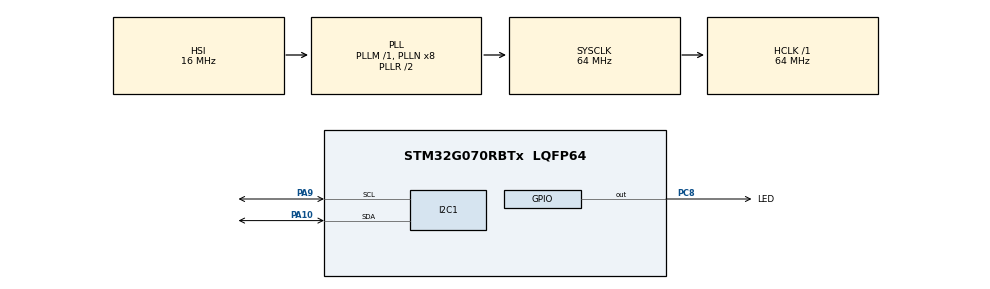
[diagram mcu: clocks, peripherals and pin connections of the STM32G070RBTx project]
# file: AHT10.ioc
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I2C1.Timing=0x10707DBC
Mcu.Family=STM32G0
Mcu.Name=STM32G070RBTx
Mcu.Package=LQFP64
NVIC.I2C1_IRQn=true\:0\:0\:false\:false\:true\:true\:true
PA10.Mode=I2C
PA10.Signal=I2C1_SDA
PA9.Mode=I2C
PA9.Signal=I2C1_SCL
PC8.GPIO_Label=LED
PC8.PinState=GPIO_PIN_SET
PC8.Signal=GPIO_Output
PF0-OSC_IN\ (PF0).Mode=HSE-External-Oscillator
PF0-OSC_IN\ (PF0).Signal=RCC_OSC_IN
PF1-OSC_OUT\ (PF1).Mode=HSE-External-Oscillator
PF1-OSC_OUT\ (PF1).Signal=RCC_OSC_OUT
ProjectManager.HeapSize=0x200
ProjectManager.StackSize=0x400
ProjectManager.TargetToolchain=MDK-ARM V5.32
RCC.ADCFreq_Value=64000000
RCC.AHBFreq_Value=64000000
RCC.CortexFreq_Value=64000000
RCC.EXTERNAL_CLOCK_VALUE=48000
RCC.HCLKFreq_Value=64000000
RCC.HSE_VALUE=12000000
RCC.HSI_VALUE=16000000
RCC.LSE_VALUE=32768
RCC.SYSCLKFreq_VALUE=64000000
RCC.SYSCLKSource=RCC_SYSCLKSOURCE_PLLCLK
RCC.VCOOutputFreq_Value=128000000
VP_SYS_VS_DBSignals.Mode=DisableDeadBatterySignals
board=custom

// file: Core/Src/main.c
/* USER CODE BEGIN Header */
/**
  ******************************************************************************
  * @file           : main.c
  * @brief          : Main program body
  ******************************************************************************
  * @attention
  *
  * Copyright (c) 2022 STMicroelectronics.
  * All rights reserved.
  *
  * This software is licensed under terms that can be found in the LICENSE file
  * in the root directory of this software component.
  * If no LICENSE file comes with this software, it is provided AS-IS.
  *
  ******************************************************************************
  */
/* USER CODE END Header */
#include "main.h"
#include "i2c.h"
#include "gpio.h"

/* USER CODE BEGIN Includes */
#include "aht10.h"
/* USER CODE END Includes */

void SystemClock_Config(void);

int main(void)
{
  /* USER CODE BEGIN 1 */
	AHT10_DATA aht10_data;
  /* USER CODE END 1 */

  /* MCU Configuration--------------------------------------------------------*/

  /* Reset of all peripherals, Initializes the Flash interface and the Systick. */
  HAL_Init();

  /* Configure the system clock */
  SystemClock_Config();

  /* Initialize all configured peripherals */
  MX_GPIO_Init();
  MX_I2C1_Init();

  /* Infinite loop */
  while (1)
  {

    /* USER CODE BEGIN 3 */
		AHT10_Process();
		AHT10_Get(&aht10_data);
		HAL_GPIO_TogglePin(LED_GPIO_Port, LED_Pin);
		HAL_Delay(100);
  }
  /* USER CODE END 3 */
}

void SystemClock_Config(void)
{
  RCC_OscInitTypeDef RCC_OscInitStruct = {0};
  RCC_ClkInitTypeDef RCC_ClkInitStruct = {0};

  /** Configure the main internal regulator output voltage
  */
  HAL_PWREx_ControlVoltageScaling(PWR_REGULATOR_VOLTAGE_SCALE1);
  /** Initializes the RCC Oscillators according to the specified parameters
  * in the RCC_OscInitTypeDef structure.
  */
  RCC_OscInitStruct.OscillatorType = RCC_OSCILLATORTYPE_HSI;
  RCC_OscInitStruct.HSIState = RCC_HSI_ON;
  RCC_OscInitStruct.HSIDiv = RCC_HSI_DIV1;
  RCC_OscInitStruct.HSICalibrationValue = RCC_HSICALIBRATION_DEFAULT;
  RCC_OscInitStruct.PLL.PLLState = RCC_PLL_ON;
  RCC_OscInitStruct.PLL.PLLSource = RCC_PLLSOURCE_HSI;
  RCC_OscInitStruct.PLL.PLLM = RCC_PLLM_DIV1;
  RCC_OscInitStruct.PLL.PLLN = 8;
  RCC_OscInitStruct.PLL.PLLP = RCC_PLLP_DIV2;
  RCC_OscInitStruct.PLL.PLLR = RCC_PLLR_DIV2;
  if (HAL_RCC_OscConfig(&RCC_OscInitStruct) != HAL_OK)
  {
    Error_Handler();
  }
  /** Initializes the CPU, AHB and APB buses clocks
  */
  RCC_ClkInitStruct.ClockType = RCC_CLOCKTYPE_HCLK|RCC_CLOCKTYPE_SYSCLK
                              |RCC_CLOCKTYPE_PCLK1;
  RCC_ClkInitStruct.SYSCLKSource = RCC_SYSCLKSOURCE_PLLCLK;
  RCC_ClkInitStruct.AHBCLKDivider = RCC_SYSCLK_DIV1;
  RCC_ClkInitStruct.APB1CLKDivider = RCC_HCLK_DIV1;

  if (HAL_RCC_ClockConfig(&RCC_ClkInitStruct, FLASH_LATENCY_2) != HAL_OK)
  {
    Error_Handler();
  }
}

void Error_Handler(void)
{
  __disable_irq();
  while (1)
  {
  }
}
